# MKL28Z7 register map
Vendor: Freescale Semiconductor, Inc.; Series: Kinetis_L; File version: 1.6
CPU: CM0PLUS r0p0, little endian, no MPU, no FPU, VTOR, 2 interrupt priority bits
Registers are 32-bit, read-write, reset 0x0 unless marked. A register's access mark holds for its fields unless they carry their own. Offsets are from the block's base; [hi:lo] are bit positions; {n}, {i} and the like mark numbered series.

## GPIOA — General Purpose Input/Output
Base 0x4000F000; register names take the prefix GPIOA_
0x00 PDOR — Port Data Output Register
  [31:0] PDO — Port Data Output
    0=Logic level 0 is driven on pin, provided pin is configured for general-purpose output; 1=Logic level 1 is driven on pin, provided pin is configured for general-purpose output
0x04 PSOR wo — Port Set Output Register
  [31:0] PTSO — Port Set Output
    0=Corresponding bit in PDORn does not change; 1=Corresponding bit in PDORn is set to logic 1
0x08 PCOR wo — Port Clear Output Register
  [31:0] PTCO — Port Clear Output
    0=Corresponding bit in PDORn does not change; 1=Corresponding bit in PDORn is cleared to logic 0
0x0C PTOR wo — Port Toggle Output Register
  [31:0] PTTO — Port Toggle Output
    0=Corresponding bit in PDORn does not change; 1=Corresponding bit in PDORn is set to the inverse of its existing logic state
0x10 PDIR ro — Port Data Input Register
  [31:0] PDI — Port Data Input
    0=Pin logic level is logic 0, or is not configured for use by digital function; 1=Pin logic level is logic 1
0x14 PDDR — Port Data Direction Register
  [31:0] PDD — Port Data Direction
    0=Pin is configured as general-purpose input, for the GPIO function; 1=Pin is configured as general-purpose output, for the GPIO function

## GPIOB — General Purpose Input/Output
Base 0x4000F040; register names take the prefix GPIOB_
Registers as GPIOA.

## GPIOC — General Purpose Input/Output
Base 0x4000F080; register names take the prefix GPIOC_
Registers as GPIOA.

## GPIOD — General Purpose Input/Output
Base 0x4000F0C0; register names take the prefix GPIOD_
Registers as GPIOA.

## GPIOE — General Purpose Input/Output
Base 0x4000F100; register names take the prefix GPIOE_
Registers as GPIOA.

## FGPIOA — General Purpose Input/Output
Base 0xF8000000; register names take the prefix FGPIOA_
Registers as GPIOA.

## DMAMUX0 — DMA channel multiplexor
Base 0x40021000; register names take the prefix DMAMUX0_
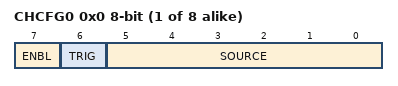
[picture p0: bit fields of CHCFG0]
{0x0+i} CHCFG{i} (i=0..7) 8-bit — Channel Configuration register
  [7] ENBL — DMA Channel Enable
    0=DMA channel is disabled. This mode is primarily used during configuration of the DMAMux. The DMA has separate channel enables/disables, which should be used to disable or reconfigure a DMA channel.; 1=DMA channel is enabled
  [6] TRIG — DMA Channel Trigger Enable
    0=Triggering is disabled. If triggering is disabled and ENBL is set, the DMA Channel will simply route the specified source to the DMA channel. (Normal mode); 1=Triggering is enabled. If triggering is enabled and ENBL is set, the DMAMUX is in Periodic Trigger mode.
  [5:0] SOURCE — DMA Channel Source (Slot)

## INTMUX0 — Interrupt Multiplexer
Base 0x40024000; register names take the prefix INTMUX0_
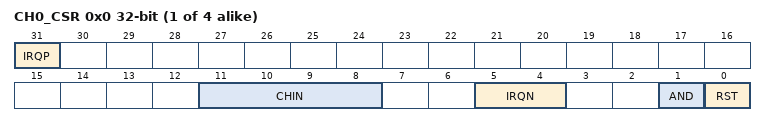
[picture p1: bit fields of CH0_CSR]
{0x0+0x40*i} CH{i}_CSR (i=0..3) — Channel n Control Status Register
  [31] IRQP ro — Channel Interrupt Request Pending
    0=No interrupt is pending; 1=The interrupt output of this channel is pending
  [11:8] CHIN ro — Channel Instance Number
  [5:4] IRQN ro — Channel Input Number
    0=32 interrupt inputs
  [1] AND — Logic AND
    0=Logic OR all enabled interrupt inputs; 1=Logic AND all enabled interrupt inputs
  [0] RST — Software Reset
    0=No operation; 1=Perform a software reset on this channel
{0x4+0x40*i} CH{i}_VEC (i=0..3) ro — Channel n Vector Number Register
  [13:2] VECN — Vector Number
{0x10+0x40*i} CH{i}_IER_31_0 (i=0..3) — Channel n Interrupt Enable Register
  [31:0] INTE — Interrupt Enable
    0=Interrupt is disabled; 1=Interrupt is enabled
{0x20+0x40*i} CH{i}_IPR_31_0 (i=0..3) ro — Channel n Interrupt Pending Register
  [31:0] INTP — Interrupt Pending
    0=No interrupt; 1=Interrupt is pending

## Notices in the file
Redistribution and use in source and binary forms, with or without modification,
are permitted provided that the following conditions are met:
o Redistributions of source code must retain the above copyright notice, this list
of conditions and the following disclaimer.
o Redistributions in binary form must reproduce the above copyright notice, this
list of conditions and the following disclaimer in the documentation and/or
other materials provided with the distribution.
o Neither the name of Freescale Semiconductor, Inc. nor the names of its
contributors may be used to endorse or promote products derived from this
software without specific prior written permission.
THIS SOFTWARE IS PROVIDED BY THE COPYRIGHT HOLDERS AND CONTRIBUTORS "AS IS" AND
ANY EXPRESS OR IMPLIED WARRANTIES, INCLUDING, BUT NOT LIMITED TO, THE IMPLIED
WARRANTIES OF MERCHANTABILITY AND FITNESS FOR A PARTICULAR PURPOSE ARE
DISCLAIMED. IN NO EVENT SHALL THE COPYRIGHT HOLDER OR CONTRIBUTORS BE LIABLE FOR
ANY DIRECT, INDIRECT, INCIDENTAL, SPECIAL, EXEMPLARY, OR CONSEQUENTIAL DAMAGES
(INCLUDING, BUT NOT LIMITED TO, PROCUREMENT OF SUBSTITUTE GOODS OR SERVICES;
LOSS OF USE, DATA, OR PROFITS; OR BUSINESS INTERRUPTION) HOWEVER CAUSED AND ON
ANY THEORY OF LIABILITY, WHETHER IN CONTRACT, STRICT LIABILITY, OR TORT
(INCLUDING NEGLIGENCE OR OTHERWISE) ARISING IN ANY WAY OUT OF THE USE OF THIS
SOFTWARE, EVEN IF ADVISED OF THE POSSIBILITY OF SUCH DAMAGE.
